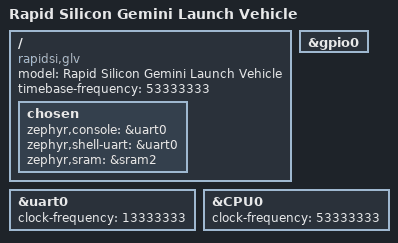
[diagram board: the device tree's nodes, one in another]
/*
 * Copyright (c) 2021 Andes Technology Corporation
 *
 * SPDX-License-Identifier: Apache-2.0
 */

 /dts-v1/;

 #include <rapidsi/rapidsi_gemini.dtsi>
 
 / {
     model = "Rapid Silicon Gemini Launch Vehicle";
     compatible = "rapidsi,glv";
     timebase-frequency = <53333333>; // 53.3MHz for fpga only
     chosen {
         zephyr,console = &uart0;
         zephyr,shell-uart = &uart0;
         zephyr,sram = &sram2;
     };
 };
 
 &gpio0 {
     status = "okay";
 };
 
 &uart0 {
     clock-frequency = <13333333>; // 13.3MHz for fpga only
 };
 
 &CPU0 {
     clock-frequency = <53333333>; // 13.3MHz for fpga only
 };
